# M440 register map
File version: 0.1
Registers are 32-bit, read-write, reset 0x0 unless marked. A register's access mark holds for its fields unless they carry their own. Offsets are from the block's base; [hi:lo] are bit positions; {n}, {i} and the like mark numbered series.

## PAB — Port AB
Base 0x400C1500
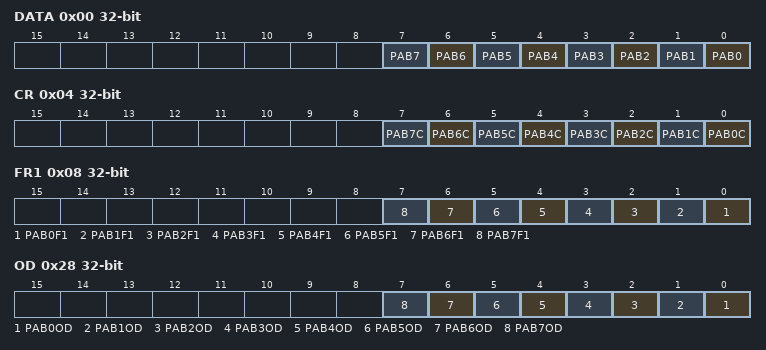
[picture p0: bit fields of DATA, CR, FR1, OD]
0x00 DATA — Port AB Data Register
  [n] PAB{n} (n=0..7)
0x04 CR — Port AB OutPABt Control Register
  [n] PAB{n}C (n=0..7)
0x08 FR1 — Port AB Function Register 1
  [n] PAB{n}F1 (n=0..7)
0x28 OD — Port AB Open Drain Control Register
  [n] PAB{n}OD (n=0..7)
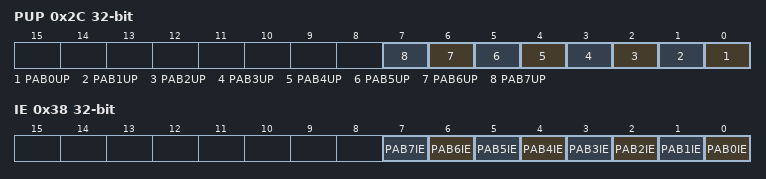
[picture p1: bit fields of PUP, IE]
0x2C PUP — Port AB PABll-up Control Register
  [n] PAB{n}UP (n=0..7)
0x38 IE — Port AB InPABt Control Register
  [n] PAB{n}IE (n=0..7)

## PAC — Port AC
Base 0x400C1600
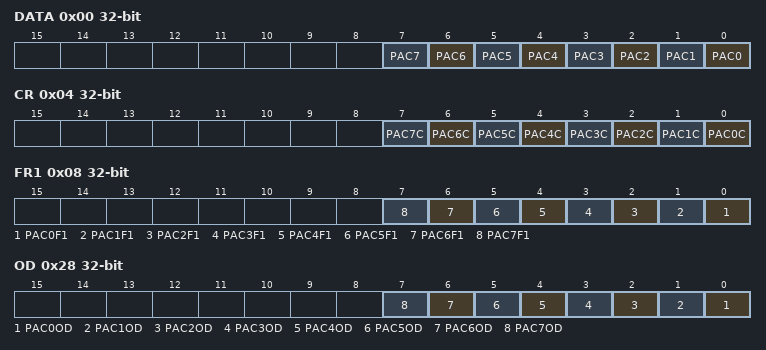
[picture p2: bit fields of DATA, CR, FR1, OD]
0x00 DATA — Port AC Data Register
  [n] PAC{n} (n=0..7)
0x04 CR — Port AC OutPACt Control Register
  [n] PAC{n}C (n=0..7)
0x08 FR1 — Port AC Function Register 1
  [n] PAC{n}F1 (n=0..7)
0x28 OD — Port AC Open Drain Control Register
  [n] PAC{n}OD (n=0..7)
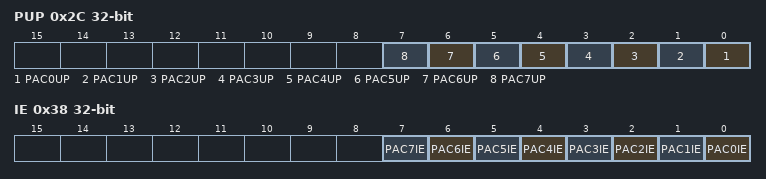
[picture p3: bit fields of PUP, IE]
0x2C PUP — Port AC PACll-up Control Register
  [n] PAC{n}UP (n=0..7)
0x38 IE — Port AC InPACt Control Register
  [n] PAC{n}IE (n=0..7)

## PAD — Port AD
Base 0x400C1700
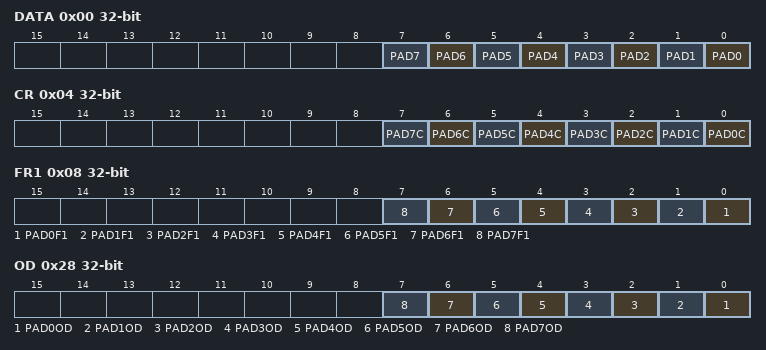
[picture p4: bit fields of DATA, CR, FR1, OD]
0x00 DATA — Port AD Data Register
  [n] PAD{n} (n=0..7)
0x04 CR — Port AD OutPADt Control Register
  [n] PAD{n}C (n=0..7)
0x08 FR1 — Port AD Function Register 1
  [n] PAD{n}F1 (n=0..7)
0x28 OD — Port AD Open Drain Control Register
  [n] PAD{n}OD (n=0..7)
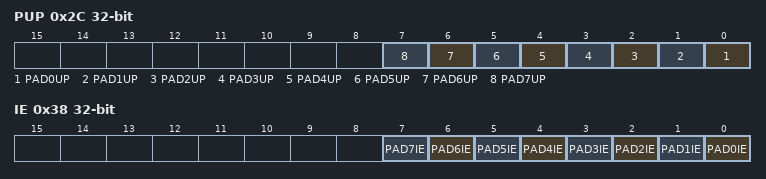
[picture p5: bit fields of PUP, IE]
0x2C PUP — Port AD PADll-up Control Register
  [n] PAD{n}UP (n=0..7)
0x38 IE — Port AD InPADt Control Register
  [n] PAD{n}IE (n=0..7)

## PAE — Port AE
Base 0x400C1800
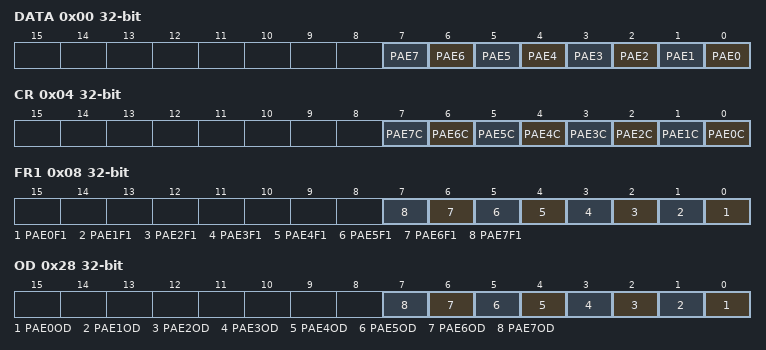
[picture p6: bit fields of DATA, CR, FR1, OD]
0x00 DATA — Port AE Data Register
  [n] PAE{n} (n=0..7)
0x04 CR — Port AE OutPAEt Control Register
  [n] PAE{n}C (n=0..7)
0x08 FR1 — Port AE Function Register 1
  [n] PAE{n}F1 (n=0..7)
0x28 OD — Port AE Open Drain Control Register
  [n] PAE{n}OD (n=0..7)
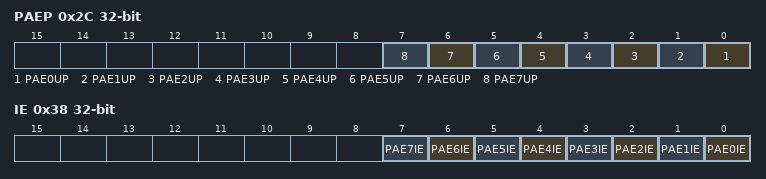
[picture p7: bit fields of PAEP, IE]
0x2C PAEP — Port AE PAEll-up Control Register
  [n] PAE{n}UP (n=0..7)
0x38 IE — Port AE InPAEt Control Register
  [n] PAE{n}IE (n=0..7)

## PAF — Port AF
Base 0x400C1900
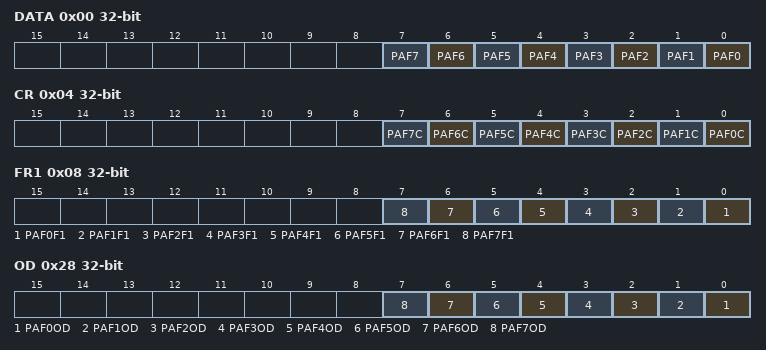
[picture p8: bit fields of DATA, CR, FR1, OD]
0x00 DATA — Port AF Data Register
  [n] PAF{n} (n=0..7)
0x04 CR — Port AF OutPAFt Control Register
  [n] PAF{n}C (n=0..7)
0x08 FR1 — Port AF Function Register 1
  [n] PAF{n}F1 (n=0..7)
0x28 OD — Port AF Open Drain Control Register
  [n] PAF{n}OD (n=0..7)
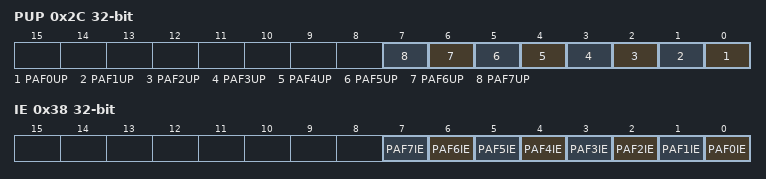
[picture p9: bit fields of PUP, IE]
0x2C PUP — Port AF PAFll-up Control Register
  [n] PAF{n}UP (n=0..7)
0x38 IE — Port AF InPAFt Control Register
  [n] PAF{n}IE (n=0..7)

## PAG — Port AG
Base 0x400C1A00
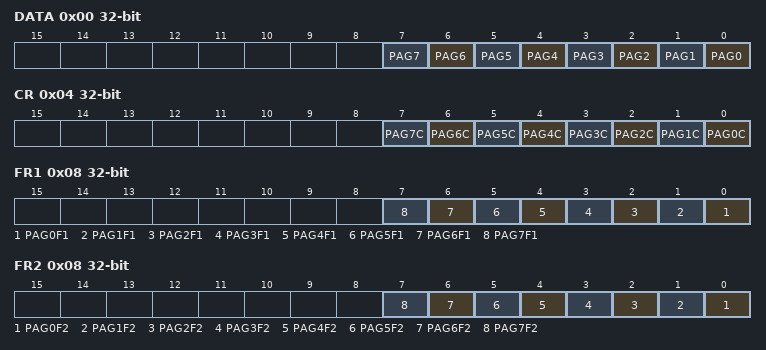
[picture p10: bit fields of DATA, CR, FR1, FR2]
0x00 DATA — Port AG Data Register
  [n] PAG{n} (n=0..7)
0x04 CR — Port AG OutPAGt Control Register
  [n] PAG{n}C (n=0..7)
0x08 FR1 — Port AG Function Register 1
  [n] PAG{n}F1 (n=0..7)
0x08 FR2 — Port AG Function Register 1
  [n] PAG{n}F2 (n=0..7)
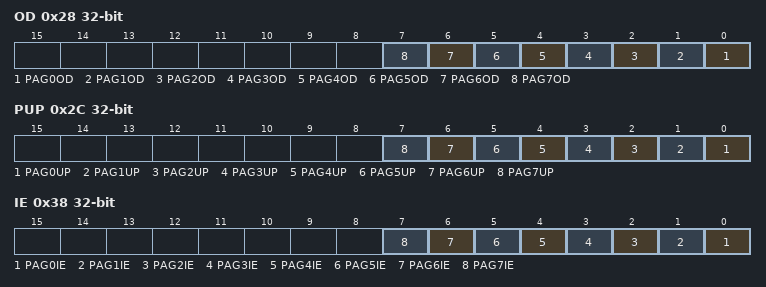
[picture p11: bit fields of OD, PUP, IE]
0x28 OD — Port AG Open Drain Control Register
  [n] PAG{n}OD (n=0..7)
0x2C PUP — Port AG PAGll-up Control Register
  [n] PAG{n}UP (n=0..7)
0x38 IE — Port AG InPAGt Control Register
  [n] PAG{n}IE (n=0..7)

## PAH — Port AH
Base 0x400C1B00
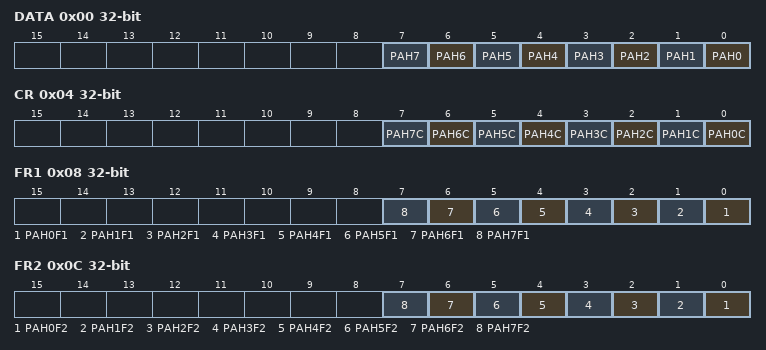
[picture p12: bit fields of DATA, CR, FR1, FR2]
0x00 DATA — Port AH Data Register
  [n] PAH{n} (n=0..7)
0x04 CR — Port AH OutPAHt Control Register
  [n] PAH{n}C (n=0..7)
0x08 FR1 — Port AH Function Register 1
  [n] PAH{n}F1 (n=0..7)
0x0C FR2 — Port AH Function Register 2
  [n] PAH{n}F2 (n=0..7)
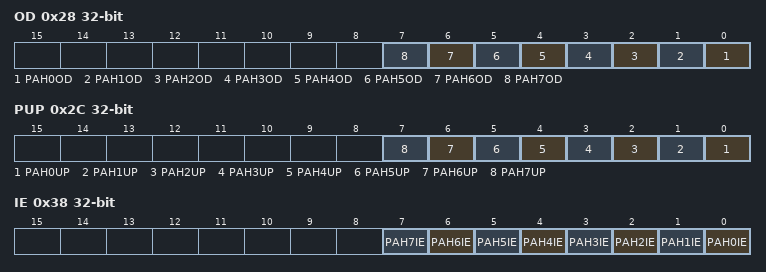
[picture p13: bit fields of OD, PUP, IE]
0x28 OD — Port AH Open Drain Control Register
  [n] PAH{n}OD (n=0..7)
0x2C PUP — Port AH PAHll-up Control Register
  [n] PAH{n}UP (n=0..7)
0x38 IE — Port AH InPAHt Control Register
  [n] PAH{n}IE (n=0..7)

## PAJ — Port AJ
Base 0x400C1C00
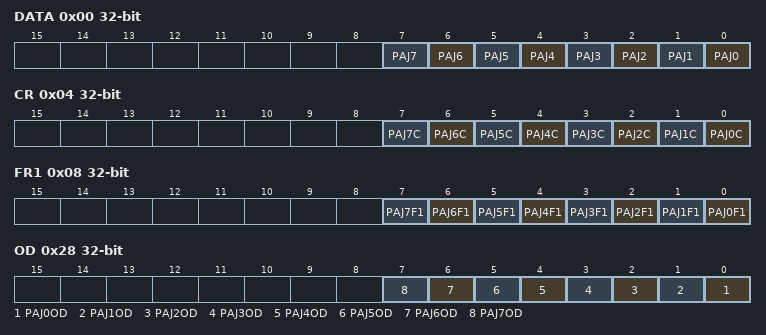
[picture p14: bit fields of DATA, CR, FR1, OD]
0x00 DATA — Port AJ Data Register
  [n] PAJ{n} (n=0..7)
0x04 CR — Port AJ OutPAJt Control Register
  [n] PAJ{n}C (n=0..7)
0x08 FR1 — Port AJ Function Register 1
  [n] PAJ{n}F1 (n=0..7)
0x28 OD — Port AJ Open Drain Control Register
  [n] PAJ{n}OD (n=0..7)
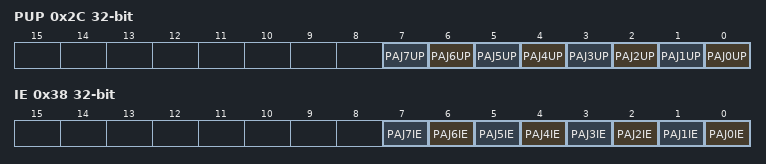
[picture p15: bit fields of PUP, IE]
0x2C PUP — Port AJ PAJll-up Control Register
  [n] PAJ{n}UP (n=0..7)
0x38 IE — Port AJ InPAJt Control Register
  [n] PAJ{n}IE (n=0..7)

## TB0 — 16-bit Timer_Event Counter (TB)
Base 0x440C4000
Same registers: TB{n} {0x400C4600+0x100*n} (n=10..19), TB{n} {0x440C4000+0x100*n} (n=1..9)
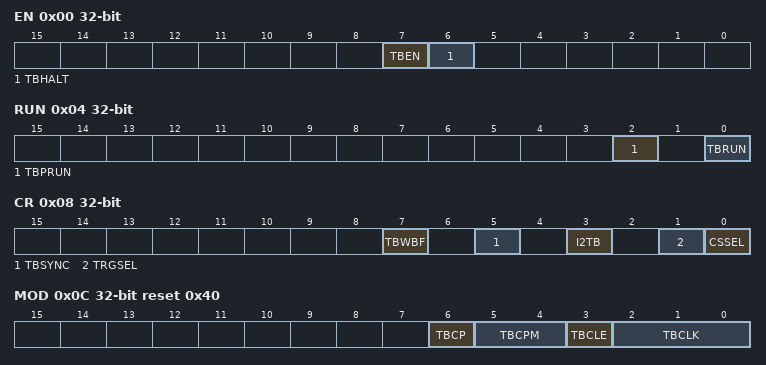
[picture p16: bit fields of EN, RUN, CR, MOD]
0x00 EN — TB Enable Register
  [7] TBEN, [6] TBHALT
0x04 RUN — TB RUN Register
  [2] TBPRUN, [0] TBRUN
0x08 CR — TB Control Register
  [7] TBWBF, [5] TBSYNC, [3] I2TB, [1] TRGSEL, [0] CSSEL
0x0C MOD reset 0x40 — TB Mode Register
  [6] TBCP wo, [5:4] TBCPM, [3] TBCLE, [2:0] TBCLK
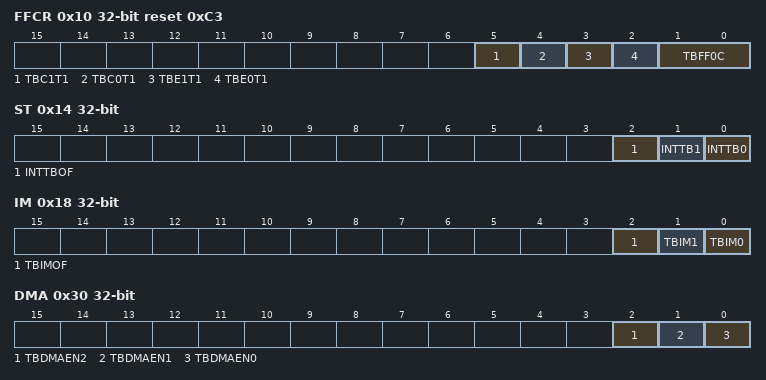
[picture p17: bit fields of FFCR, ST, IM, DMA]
0x10 FFCR reset 0xC3 — TB Flip-Flop Control Register
  [5] TBC1T1, [4] TBC0T1, [3] TBE1T1, [2] TBE0T1, [1:0] TBFF0C
0x14 ST ro — TB Status Register
  [2] INTTBOF, [1] INTTB1, [0] INTTB0
0x18 IM — TB Interrupt Mask Register
  [2] TBIMOF, [1] TBIM1, [0] TBIM0
0x1C UC ro — TB Read Capture Register
  [15:0] TBUC
0x20 RG0 — TB RG0 Timer Register
  [15:0] TBRG0
0x24 RG1 — TB RG1 Timer Register
  [15:0] TBRG1
0x28 CP0 ro (reset mask 0xFFFF0000) — TB CP0 Capture Register
  [15:0] TBCP0
0x2C CP1 ro (reset mask 0xFFFF0000) — TB CP1 Capture Register
  [15:0] TBCP1
0x30 DMA — TB DMA Enable Register
  [2] TBDMAEN2, [1] TBDMAEN1, [0] TBDMAEN0
